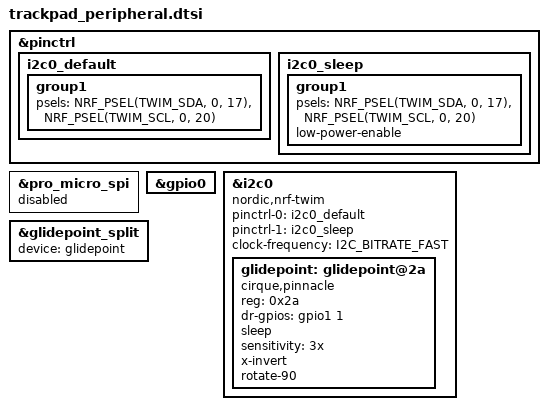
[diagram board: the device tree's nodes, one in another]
#include "cirque_pinnacle.dtsi"

// https://github.com/zmkfirmware/zmk/blob/e93cd31a5866cd4f50385bece7a3fb770f2ca6f8/app/boards/arm/nice_nano/nice_nano-pinctrl.dtsi

&pinctrl {
    /* configuration for i2c0 device, default state */
    i2c0_default: i2c0_default {
        group1 {
            psels = <NRF_PSEL(TWIM_SDA, 0, 17)>,
                <NRF_PSEL(TWIM_SCL, 0, 20)>;
        };
    };

    i2c0_sleep: i2c0_sleep {
        group1 {
            psels = <NRF_PSEL(TWIM_SDA, 0, 17)>,
                <NRF_PSEL(TWIM_SCL, 0, 20)>;
            low-power-enable;
        };
    };
};

&pro_micro_spi {
    status = "disabled";
};

// -----------------------------------

/* cirque trackpad I2C pins */
/* See: https://zmk.dev/docs/development/hardware-integration/pointing?part-type=peripheral#input-device */

&gpio0 {
    status = "okay";
};

&cirque_pinnacle_i2c: &i2c0 {
    compatible = "nordic,nrf-twim";
    status = "okay";

    pinctrl-0 = <&i2c0_default>;
    pinctrl-1 = <&i2c0_sleep>;
    pinctrl-names = "default", "sleep";
    clock-frequency = <I2C_BITRATE_FAST>;

    glidepoint: glidepoint@2a {
        compatible = "cirque,pinnacle";
        status = "okay";
        reg = <0x2a>;

        //dr-gpios = <&gpio0 6 GPIO_ACTIVE_HIGH>;     // D1 pin (nice!view compatible)    
        dr-gpios = <&gpio1 1 (GPIO_ACTIVE_HIGH)>;   // P1.01 on my board

        sleep;

        sensitivity = "3x";
        x-invert;
        rotate-90;
        //x-axis-z-min = <2>;
        //y-axis-z-min = <4>;
    };
};

// Overrides for the input-split child node
&glidepoint_split {
    device = <&glidepoint>;
};
